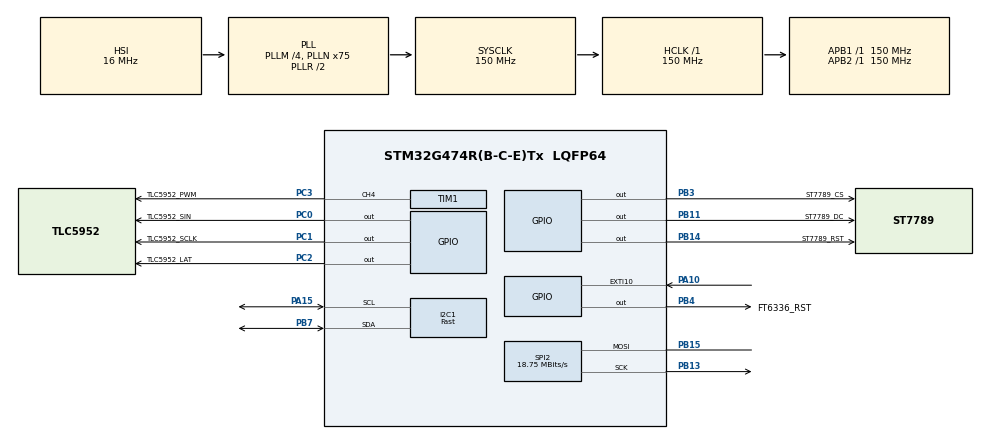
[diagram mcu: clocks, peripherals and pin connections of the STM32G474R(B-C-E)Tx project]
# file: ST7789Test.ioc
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Dma.Request0=SPI2_TX
Dma.SPI2_TX.0.Direction=DMA_MEMORY_TO_PERIPH
Dma.SPI2_TX.0.EventEnable=DISABLE
Dma.SPI2_TX.0.Instance=DMA1_Channel1
Dma.SPI2_TX.0.MemDataAlignment=DMA_MDATAALIGN_BYTE
Dma.SPI2_TX.0.MemInc=DMA_MINC_ENABLE
Dma.SPI2_TX.0.Mode=DMA_NORMAL
Dma.SPI2_TX.0.PeriphDataAlignment=DMA_PDATAALIGN_BYTE
Dma.SPI2_TX.0.PeriphInc=DMA_PINC_DISABLE
Dma.SPI2_TX.0.Polarity=HAL_DMAMUX_REQ_GEN_RISING
Dma.SPI2_TX.0.Priority=DMA_PRIORITY_LOW
Dma.SPI2_TX.0.RequestNumber=1
Dma.SPI2_TX.0.SignalID=NONE
Dma.SPI2_TX.0.SyncEnable=DISABLE
Dma.SPI2_TX.0.SyncPolarity=HAL_DMAMUX_SYNC_NO_EVENT
Dma.SPI2_TX.0.SyncRequestNumber=1
Dma.SPI2_TX.0.SyncSignalID=NONE
I2C1.I2C_Speed_Mode=I2C_Fast
I2C1.Timing=0x10E32879
Mcu.Family=STM32G4
Mcu.Name=STM32G474R(B-C-E)Tx
Mcu.Package=LQFP64
NVIC.DMA1_Channel1_IRQn=true\:0\:0\:false\:false\:true\:false\:true\:true
NVIC.EXTI15_10_IRQn=true\:0\:0\:false\:false\:true\:true\:true\:true
NVIC.PriorityGroup=NVIC_PRIORITYGROUP_4
NVIC.TIM7_DAC_IRQn=true\:0\:0\:false\:false\:true\:true\:true\:true
PA10.GPIO_ModeDefaultEXTI=GPIO_MODE_IT_FALLING
PA10.GPIO_PuPd=GPIO_PULLUP
PA10.Signal=GPXTI10
PA13.Mode=Serial_Wire
PA13.Signal=SYS_JTMS-SWDIO
PA14.Mode=Serial_Wire
PA14.Signal=SYS_JTCK-SWCLK
PA15.GPIO_Pu=GPIO_PULLUP
PA15.GPIO_Speed=GPIO_SPEED_FREQ_VERY_HIGH
PA15.Mode=I2C
PA15.Signal=I2C1_SCL
PB11.GPIO_Label=ST7789_DC
PB11.Signal=GPIO_Output
PB13.Mode=Simplex_Bidirectional_Master
PB13.Signal=SPI2_SCK
PB14.GPIO_Label=ST7789_RST
PB14.Signal=GPIO_Output
PB15.Mode=Simplex_Bidirectional_Master
PB15.Signal=SPI2_MOSI
PB3.GPIO_Label=ST7789_CS
PB3.Signal=GPIO_Output
PB4.GPIO_Label=FT6336_RST
PB4.GPIO_PuPd=GPIO_PULLUP
PB4.GPIO_Speed=GPIO_SPEED_FREQ_HIGH
PB4.PinState=GPIO_PIN_RESET
PB4.Signal=GPIO_Output
PB7.GPIO_Pu=GPIO_PULLUP
PB7.GPIO_Speed=GPIO_SPEED_FREQ_VERY_HIGH
PB7.Mode=I2C
PB7.Signal=I2C1_SDA
PC0.GPIO_Label=TLC5952_SIN
PC0.Signal=GPIO_Output
PC1.GPIO_Label=TLC5952_SCLK
PC1.Signal=GPIO_Output
PC2.GPIO_Label=TLC5952_LAT
PC2.Signal=GPIO_Output
PC3.GPIO_Label=TLC5952_PWM
PC3.Signal=S_TIM1_CH4
PF0-OSC_IN.Mode=HSE-External-Oscillator
PF0-OSC_IN.Signal=RCC_OSC_IN
PF1-OSC_OUT.Mode=HSE-External-Oscillator
PF1-OSC_OUT.Signal=RCC_OSC_OUT
ProjectManager.HeapSize=0x1000
ProjectManager.StackSize=0x1000
ProjectManager.TargetToolchain=STM32CubeIDE
RCC.ADC12Freq_Value=150000000
RCC.ADC345Freq_Value=150000000
RCC.AHBFreq_Value=150000000
RCC.APB1Freq_Value=150000000
RCC.APB1TimFreq_Value=150000000
RCC.APB2Freq_Value=150000000
RCC.APB2TimFreq_Value=150000000
RCC.CortexFreq_Value=150000000
RCC.EXTERNAL_CLOCK_VALUE=12288000
RCC.HCLKFreq_Value=150000000
RCC.HSE_VALUE=8000000
RCC.HSI48_VALUE=48000000
RCC.HSI_VALUE=16000000
RCC.LSE_VALUE=32768
RCC.PLLM=RCC_PLLM_DIV4
RCC.PLLN=75
RCC.SYSCLKFreq_VALUE=150000000
RCC.SYSCLKSource=RCC_SYSCLKSOURCE_PLLCLK
RCC.USBFreq_Value=150000000
RCC.VCOOutputFreq_Value=300000000
SH.S_TIM1_CH4.0=TIM1_CH4,PWM Generation4 CH4
SPI2.BaudRatePrescaler=SPI_BAUDRATEPRESCALER_8
SPI2.CLKPolarity=SPI_POLARITY_HIGH
SPI2.CalculateBaudRate=18.75 MBits/s
SPI2.DataSize=SPI_DATASIZE_8BIT
SPI2.Direction=SPI_DIRECTION_1LINE
SPI2.Mode=SPI_MODE_MASTER
SPI2.VirtualType=VM_MASTER
TIM1.Channel-PWM\ Generation4\ CH4=TIM_CHANNEL_4
TIM1.PeriodNoDither=1000
TIM1.Prescaler=150-1
TIM1.PulseNoDither_4=995
TIM7.PeriodNoDither=1000
TIM7.Prescaler=60-1
VP_SYS_VS_DBSignals.Mode=DisableDeadBatterySignals
VP_TIM7_VS_ClockSourceINT.Mode=Enable_Timer
board=custom

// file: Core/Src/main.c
/* USER CODE BEGIN Header */
/**
  ******************************************************************************
  * @file           : main.c
  * @brief          : Main program body
  ******************************************************************************
  * @attention
  *
  * Copyright (c) 2025 STMicroelectronics.
  * All rights reserved.
  *
  * This software is licensed under terms that can be found in the LICENSE file
  * in the root directory of this software component.
  * If no LICENSE file comes with this software, it is provided AS-IS.
  *
  ******************************************************************************
  */
/* USER CODE END Header */
#include "main.h"

/* USER CODE BEGIN Includes */

#include "ft6336.h"

#include "st7789.h"

#include "TLC5952.h"

/* USER CODE END Includes */

I2C_HandleTypeDef hi2c1;

SPI_HandleTypeDef hspi2;
DMA_HandleTypeDef hdma_spi2_tx;

TIM_HandleTypeDef htim1;
TIM_HandleTypeDef htim7;

/* USER CODE BEGIN PV */

//TouchPoints_HandleTypeDef TouchPoints;

/* USER CODE END PV */

void SystemClock_Config(void);
static void MX_GPIO_Init(void);
static void MX_DMA_Init(void);
static void MX_SPI2_Init(void);
static void MX_I2C1_Init(void);
static void MX_TIM7_Init(void);
static void MX_TIM1_Init(void);

int main(void)
{

  /* MCU Configuration--------------------------------------------------------*/

  /* Reset of all peripherals, Initializes the Flash interface and the Systick. */
  HAL_Init();

  /* Configure the system clock */
  SystemClock_Config();

  /* Initialize all configured peripherals */
  MX_GPIO_Init();
  MX_DMA_Init();
  MX_SPI2_Init();
  MX_I2C1_Init();
  MX_TIM7_Init();
  MX_TIM1_Init();
  /* USER CODE BEGIN 2 */

  ST7789_Init();
  FT6336_Init();
  TLC5952_Init();

  HAL_TIM_Base_Start(&htim1);
  HAL_TIM_PWM_Start(&htim1, TIM_CHANNEL_4);

  /* USER CODE END 2 */

  /* Infinite loop */
  /* USER CODE BEGIN WHILE */
  while (1)
  {

	    TLC5952_WriteLED();  // 发送数据
	    TLC5952_WriteControl();

		  HAL_Delay(100);        // 延时 1 秒

//		ST7789_WriteString(10, 14, "Measuring", Font_11x18, BLACK, WHITE);
//
//		ST7789_WriteString(160, 14, "Orange", Font_16x26, BROWN, WHITE);
//
//
//		ST7789_WriteString(10, 54, "Sugar Content", Font_11x18, BLACK, WHITE);
//
//		ST7789_WriteString(160, 50, "8", Font_16x26, MAGENTA, WHITE);

//		ST7789_WriteString(10, 50, "NIR", Font_16x26, RED, BLACK);
//		ST7789_WriteString(10, 80, "Sugar ", Font_16x26, GREEN, BLACK);
//		ST7789_WriteString(10, 110, "Content", Font_16x26, GREEN, BLACK);
//		ST7789_WriteString(10, 140, "Meter", Font_16x26, BLUE, BLACK);
//		ST7789_WriteString(100, 200, "Press Any Key to Start", Font_7x10, WHITE, BLACK);

//	    lv_tick_inc(1);
//	    lv_task_handler();
//	    HAL_Delay(1);

//	  HAL_Delay(10);

//	  ST7789_DrawPixel(TouchPoints.point1_y, 240-TouchPoints.point1_x, 0xffffff);
//	  ST7789_DrawPixel(TouchPoints.point2_y, 240-TouchPoints.point2_x, 0xffffff);

    /* USER CODE END WHILE */

  }
}

void SystemClock_Config(void)
{
  RCC_OscInitTypeDef RCC_OscInitStruct = {0};
  RCC_ClkInitTypeDef RCC_ClkInitStruct = {0};

  /** Configure the main internal regulator output voltage
  */
  HAL_PWREx_ControlVoltageScaling(PWR_REGULATOR_VOLTAGE_SCALE1);

  /** Initializes the RCC Oscillators according to the specified parameters
  * in the RCC_OscInitTypeDef structure.
  */
  RCC_OscInitStruct.OscillatorType = RCC_OSCILLATORTYPE_HSI;
  RCC_OscInitStruct.HSIState = RCC_HSI_ON;
  RCC_OscInitStruct.HSICalibrationValue = RCC_HSICALIBRATION_DEFAULT;
  RCC_OscInitStruct.PLL.PLLState = RCC_PLL_ON;
  RCC_OscInitStruct.PLL.PLLSource = RCC_PLLSOURCE_HSI;
  RCC_OscInitStruct.PLL.PLLM = RCC_PLLM_DIV4;
  RCC_OscInitStruct.PLL.PLLN = 75;
  RCC_OscInitStruct.PLL.PLLP = RCC_PLLP_DIV2;
  RCC_OscInitStruct.PLL.PLLQ = RCC_PLLQ_DIV2;
  RCC_OscInitStruct.PLL.PLLR = RCC_PLLR_DIV2;
  if (HAL_RCC_OscConfig(&RCC_OscInitStruct) != HAL_OK)
  {
    Error_Handler();
  }

  /** Initializes the CPU, AHB and APB buses clocks
  */
  RCC_ClkInitStruct.ClockType = RCC_CLOCKTYPE_HCLK|RCC_CLOCKTYPE_SYSCLK
                              |RCC_CLOCKTYPE_PCLK1|RCC_CLOCKTYPE_PCLK2;
  RCC_ClkInitStruct.SYSCLKSource = RCC_SYSCLKSOURCE_PLLCLK;
  RCC_ClkInitStruct.AHBCLKDivider = RCC_SYSCLK_DIV1;
  RCC_ClkInitStruct.APB1CLKDivider = RCC_HCLK_DIV1;
  RCC_ClkInitStruct.APB2CLKDivider = RCC_HCLK_DIV1;

  if (HAL_RCC_ClockConfig(&RCC_ClkInitStruct, FLASH_LATENCY_4) != HAL_OK)
  {
    Error_Handler();
  }
}

static void MX_I2C1_Init(void)
{

  hi2c1.Instance = I2C1;
  hi2c1.Init.Timing = 0x10E32879;
  hi2c1.Init.OwnAddress1 = 0;
  hi2c1.Init.AddressingMode = I2C_ADDRESSINGMODE_7BIT;
  hi2c1.Init.DualAddressMode = I2C_DUALADDRESS_DISABLE;
  hi2c1.Init.OwnAddress2 = 0;
  hi2c1.Init.OwnAddress2Masks = I2C_OA2_NOMASK;
  hi2c1.Init.GeneralCallMode = I2C_GENERALCALL_DISABLE;
  hi2c1.Init.NoStretchMode = I2C_NOSTRETCH_DISABLE;
  if (HAL_I2C_Init(&hi2c1) != HAL_OK)
  {
    Error_Handler();
  }

  /** Configure Analogue filter
  */
  if (HAL_I2CEx_ConfigAnalogFilter(&hi2c1, I2C_ANALOGFILTER_ENABLE) != HAL_OK)
  {
    Error_Handler();
  }

  /** Configure Digital filter
  */
  if (HAL_I2CEx_ConfigDigitalFilter(&hi2c1, 0) != HAL_OK)
  {
    Error_Handler();
  }

}

static void MX_SPI2_Init(void)
{

  /* SPI2 parameter configuration*/
  hspi2.Instance = SPI2;
  hspi2.Init.Mode = SPI_MODE_MASTER;
  hspi2.Init.Direction = SPI_DIRECTION_1LINE;
  hspi2.Init.DataSize = SPI_DATASIZE_8BIT;
  hspi2.Init.CLKPolarity = SPI_POLARITY_HIGH;
  hspi2.Init.CLKPhase = SPI_PHASE_1EDGE;
  hspi2.Init.NSS = SPI_NSS_SOFT;
  hspi2.Init.BaudRatePrescaler = SPI_BAUDRATEPRESCALER_8;
  hspi2.Init.FirstBit = SPI_FIRSTBIT_MSB;
  hspi2.Init.TIMode = SPI_TIMODE_DISABLE;
  hspi2.Init.CRCCalculation = SPI_CRCCALCULATION_DISABLE;
  hspi2.Init.CRCPolynomial = 7;
  hspi2.Init.CRCLength = SPI_CRC_LENGTH_DATASIZE;
  hspi2.Init.NSSPMode = SPI_NSS_PULSE_ENABLE;
  if (HAL_SPI_Init(&hspi2) != HAL_OK)
  {
    Error_Handler();
  }

}

static void MX_TIM1_Init(void)
{

  TIM_MasterConfigTypeDef sMasterConfig = {0};
  TIM_OC_InitTypeDef sConfigOC = {0};
  TIM_BreakDeadTimeConfigTypeDef sBreakDeadTimeConfig = {0};

  htim1.Instance = TIM1;
  htim1.Init.Prescaler = 150-1;
  htim1.Init.CounterMode = TIM_COUNTERMODE_UP;
  htim1.Init.Period = 1000;
  htim1.Init.ClockDivision = TIM_CLOCKDIVISION_DIV1;
  htim1.Init.RepetitionCounter = 0;
  htim1.Init.AutoReloadPreload = TIM_AUTORELOAD_PRELOAD_DISABLE;
  if (HAL_TIM_PWM_Init(&htim1) != HAL_OK)
  {
    Error_Handler();
  }
  sMasterConfig.MasterOutputTrigger = TIM_TRGO_RESET;
  sMasterConfig.MasterOutputTrigger2 = TIM_TRGO2_RESET;
  sMasterConfig.MasterSlaveMode = TIM_MASTERSLAVEMODE_DISABLE;
  if (HAL_TIMEx_MasterConfigSynchronization(&htim1, &sMasterConfig) != HAL_OK)
  {
    Error_Handler();
  }
  sConfigOC.OCMode = TIM_OCMODE_PWM1;
  sConfigOC.Pulse = 995;
  sConfigOC.OCPolarity = TIM_OCPOLARITY_HIGH;
  sConfigOC.OCNPolarity = TIM_OCNPOLARITY_HIGH;
  sConfigOC.OCFastMode = TIM_OCFAST_DISABLE;
  sConfigOC.OCIdleState = TIM_OCIDLESTATE_RESET;
  sConfigOC.OCNIdleState = TIM_OCNIDLESTATE_RESET;
  if (HAL_TIM_PWM_ConfigChannel(&htim1, &sConfigOC, TIM_CHANNEL_4) != HAL_OK)
  {
    Error_Handler();
  }
  sBreakDeadTimeConfig.OffStateRunMode = TIM_OSSR_DISABLE;
  sBreakDeadTimeConfig.OffStateIDLEMode = TIM_OSSI_DISABLE;
  sBreakDeadTimeConfig.LockLevel = TIM_LOCKLEVEL_OFF;
  sBreakDeadTimeConfig.DeadTime = 0;
  sBreakDeadTimeConfig.BreakState = TIM_BREAK_DISABLE;
  sBreakDeadTimeConfig.BreakPolarity = TIM_BREAKPOLARITY_HIGH;
  sBreakDeadTimeConfig.BreakFilter = 0;
  sBreakDeadTimeConfig.BreakAFMode = TIM_BREAK_AFMODE_INPUT;
  sBreakDeadTimeConfig.Break2State = TIM_BREAK2_DISABLE;
  sBreakDeadTimeConfig.Break2Polarity = TIM_BREAK2POLARITY_HIGH;
  sBreakDeadTimeConfig.Break2Filter = 0;
  sBreakDeadTimeConfig.Break2AFMode = TIM_BREAK_AFMODE_INPUT;
  sBreakDeadTimeConfig.AutomaticOutput = TIM_AUTOMATICOUTPUT_DISABLE;
  if (HAL_TIMEx_ConfigBreakDeadTime(&htim1, &sBreakDeadTimeConfig) != HAL_OK)
  {
    Error_Handler();
  }
  HAL_TIM_MspPostInit(&htim1);

}

static void MX_TIM7_Init(void)
{

  TIM_MasterConfigTypeDef sMasterConfig = {0};

  htim7.Instance = TIM7;
  htim7.Init.Prescaler = 60-1;
  htim7.Init.CounterMode = TIM_COUNTERMODE_UP;
  htim7.Init.Period = 1000;
  htim7.Init.AutoReloadPreload = TIM_AUTORELOAD_PRELOAD_DISABLE;
  if (HAL_TIM_Base_Init(&htim7) != HAL_OK)
  {
    Error_Handler();
  }
  sMasterConfig.MasterOutputTrigger = TIM_TRGO_RESET;
  sMasterConfig.MasterSlaveMode = TIM_MASTERSLAVEMODE_DISABLE;
  if (HAL_TIMEx_MasterConfigSynchronization(&htim7, &sMasterConfig) != HAL_OK)
  {
    Error_Handler();
  }

}

static void MX_DMA_Init(void)
{

  /* DMA controller clock enable */
  __HAL_RCC_DMAMUX1_CLK_ENABLE();
  __HAL_RCC_DMA1_CLK_ENABLE();

  /* DMA interrupt init */
  /* DMA1_Channel1_IRQn interrupt configuration */
  HAL_NVIC_SetPriority(DMA1_Channel1_IRQn, 0, 0);
  HAL_NVIC_EnableIRQ(DMA1_Channel1_IRQn);

}

static void MX_GPIO_Init(void)
{
  GPIO_InitTypeDef GPIO_InitStruct = {0};

  /* GPIO Ports Clock Enable */
  __HAL_RCC_GPIOF_CLK_ENABLE();
  __HAL_RCC_GPIOC_CLK_ENABLE();
  __HAL_RCC_GPIOB_CLK_ENABLE();
  __HAL_RCC_GPIOA_CLK_ENABLE();

  /*Configure GPIO pin Output Level */
  HAL_GPIO_WritePin(GPIOC, TLC5952_SIN_Pin|TLC5952_SCLK_Pin|TLC5952_LAT_Pin, GPIO_PIN_RESET);

  /*Configure GPIO pin Output Level */
  HAL_GPIO_WritePin(GPIOB, ST7789_DC_Pin|ST7789_RST_Pin|ST7789_CS_Pin|FT6336_RST_Pin, GPIO_PIN_RESET);

  /*Configure GPIO pins : TLC5952_SIN_Pin TLC5952_SCLK_Pin TLC5952_LAT_Pin */
  GPIO_InitStruct.Pin = TLC5952_SIN_Pin|TLC5952_SCLK_Pin|TLC5952_LAT_Pin;
  GPIO_InitStruct.Mode = GPIO_MODE_OUTPUT_PP;
  GPIO_InitStruct.Pull = GPIO_NOPULL;
  GPIO_InitStruct.Speed = GPIO_SPEED_FREQ_LOW;
  HAL_GPIO_Init(GPIOC, &GPIO_InitStruct);

  /*Configure GPIO pins : ST7789_DC_Pin ST7789_RST_Pin ST7789_CS_Pin */
  GPIO_InitStruct.Pin = ST7789_DC_Pin|ST7789_RST_Pin|ST7789_CS_Pin;
  GPIO_InitStruct.Mode = GPIO_MODE_OUTPUT_PP;
  GPIO_InitStruct.Pull = GPIO_NOPULL;
  GPIO_InitStruct.Speed = GPIO_SPEED_FREQ_LOW;
  HAL_GPIO_Init(GPIOB, &GPIO_InitStruct);

  /*Configure GPIO pin : PA10 */
  GPIO_InitStruct.Pin = GPIO_PIN_10;
  GPIO_InitStruct.Mode = GPIO_MODE_IT_FALLING;
  GPIO_InitStruct.Pull = GPIO_PULLUP;
  HAL_GPIO_Init(GPIOA, &GPIO_InitStruct);

  /*Configure GPIO pin : FT6336_RST_Pin */
  GPIO_InitStruct.Pin = FT6336_RST_Pin;
  GPIO_InitStruct.Mode = GPIO_MODE_OUTPUT_PP;
  GPIO_InitStruct.Pull = GPIO_PULLUP;
  GPIO_InitStruct.Speed = GPIO_SPEED_FREQ_HIGH;
  HAL_GPIO_Init(FT6336_RST_GPIO_Port, &GPIO_InitStruct);

  /* EXTI interrupt init*/
  HAL_NVIC_SetPriority(EXTI15_10_IRQn, 0, 0);
  HAL_NVIC_EnableIRQ(EXTI15_10_IRQn);

}

void Error_Handler(void)
{
  __disable_irq();
  while (1)
  {
  }
}
